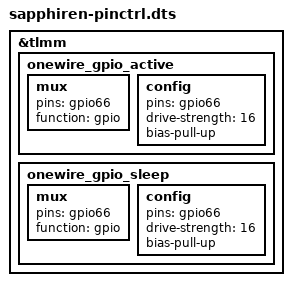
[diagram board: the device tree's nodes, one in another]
&tlmm {
	onewire_gpio_active: onewire_gpio_active {
		mux {
			pins = "gpio66";
			function = "gpio";
		};

		config {
			pins = "gpio66";
			drive-strength = <16>;
			bias-pull-up;
		};
	};

	onewire_gpio_sleep: onewire_gpio_sleep {
		mux {
			pins = "gpio66";
			function = "gpio";
		};

		config {
			pins = "gpio66";
			drive-strength = <16>;
			bias-pull-up;
		};
	};
};
